# UUPS_367.0 register map
Vendor: Texas Instruments
Peripheral module from a debugger description file (folder msp430).
Registers are 16-bit, read-only, no defined reset value unless marked. A register's access mark holds for its fields unless they carry their own. Offsets are as the file gives them; lines under a group give offsets from that group; [hi:lo] are bit positions; {n}, {i} and the like mark numbered series; 'fields as' and 'values as' point back to an identical list; <NAME> marks a mode.

## UUPS
0x00 UUPSIIDX — Interrupt Index Register
  [15:1] IIDX — UUPS Interrupt Vector Value.
    0=No Interrupt pending; 1=Interrupt Source: PTMOUT; Interrupt Priority: Highest; 2=Interrupt Source: PREQIG; 3=Interrupt Source: STPBYDB; 4=Reserved; Interrupt Priority: Lowest
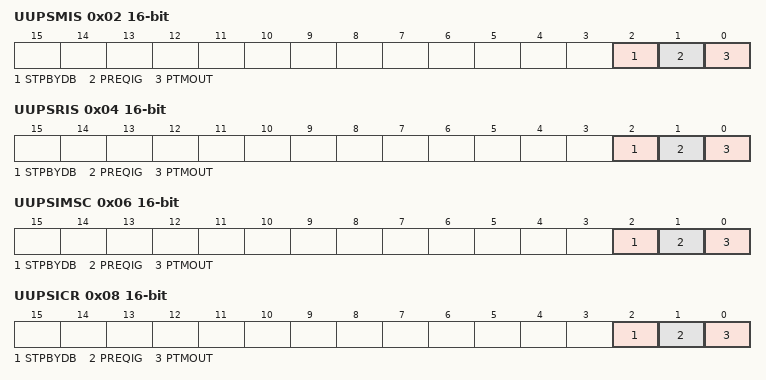
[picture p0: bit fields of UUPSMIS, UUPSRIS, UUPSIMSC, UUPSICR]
0x02 UUPSMIS — Masked Interrupt Status Register
  [all] fields
    0=No interrupt pending; 1=Interrupt pending
  [2] STPBYDB — USS has been interrupted by debug mode Masked Interrupt Status bit.
  [1] PREQIG — UUPS Power Request Ignore Masked Interrupt Status bit.
  [0] PTMOUT — UUPS Power Up Time Out Masked Interrupt Status bit.
0x04 UUPSRIS — Raw Interrupt Status Register
  [2] STPBYDB — USS has been interrupted by debug mode.
    0=USS has not been interrupted by debug halt mode; 1=USS has been interrupted by debug halt mode
  [1] PREQIG — UUPS Power Request Ignore Masked Interrupt Status and Clear bit.
    0=No USS_PWRREQ signal has been ignored; 1=USS_PWRREQ signal has been ignored
  [0] PTMOUT — UUPS Power Up Timer Out Raw Interrupt Status bit.
    0=Time out during power up has not occurred; 1=Time out during power up has occurred
0x06 UUPSIMSC rw — Interrupt Mask Register
  [2] STPBYDB — USS has been interrupted by debug mode Interrupt Mask bit.
    0=STPBYDB Interrupt is disabled; 1=STPBYDB Interrupt is enabled
  [1] PREQIG — Power Request Ignore Interrupt Mask bit.
    0=Power Request Ignore Interrupt is disabled; 1=Power Request Ignore Interrupt is enabled
  [0] PTMOUT — UUPS Power Up Time Out Interrupt Mask bit.
    0=UUPS Power Up Time Out Interrupt is disabled; 1=UUPS Power Up Time Out Interrupt is enabled
0x08 UUPSICR rw — Interrupt Clear Register.
  [2] STPBYDB — USS has been interrupted by debug mode Interrupt Clear bit.
  [1] PREQIG — Power Request Ignored Interrupt Clear bit.
  [0] PTMOUT — UUPS Power Up Time Out Interrupt Clear bit.
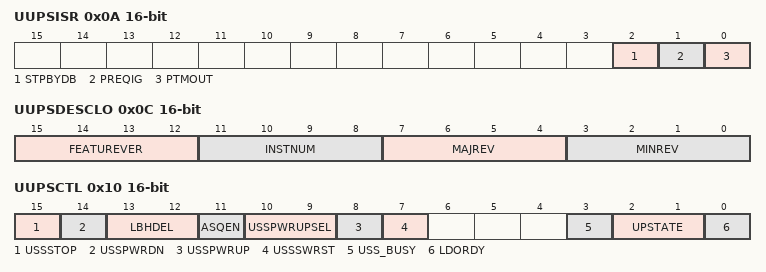
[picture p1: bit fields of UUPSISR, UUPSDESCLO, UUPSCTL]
0x0A UUPSISR rw — Interrupt Flag Set Register.
  [2] STPBYDB — USS has been interrupted by debug mode Interrupt Set bit.
  [1] PREQIG — Power Request Ignored Interrupt Set bit.
  [0] PTMOUT — UUPS Power Up Time Out Interrupt Set bit.
0x0C UUPSDESCLO — UUPS Descriptor Register L.
  [15:12] FEATUREVER — Feature Set for the module
  [11:8] INSTNUM — Instance Number within the device.
  [7:4] MAJREV — Major Revision
  [3:0] MINREV — Minor Revision
0x0E UUPSDESCHI access not given — UUPS Descriptor Register H.
0x10 UUPSCTL access per field — UUPS Control
  [15] USSSTOP rw — USS Measurement Stop
    0=No action; 1=Stop the current measurement
  [14] USSPWRDN rw — USS Power Down
    0=No action; 1=Stop the current measurement and power off the USS module
  [13:12] LBHDEL rw — Reserved_2
    0=no additional delay; 1=additional hold off delay of ~100us (512 REFCLKs); 2=additional hold off delay of ~200us (1024 REFCLKs); 3=additional hold off delay of ~300us (1536 REFCLKs)
  [11] ASQEN rw — Power Ready Output Event Select
    0=Do not generate the PSQ_START signal event to ASQ; 1=Generate the PSQ_START signal event to the ASQ
  [10:9] USSPWRUPSEL rw — USS Power Up trigger source select.
    0=CTL.USSPWRUP bit; 1=Ext. trigger (see the device specific datasheet); 2=Ext. trigger (see the device-specific data sheet); 3=Ext. trigger (see the device-specific data sheet)
  [8] USSPWRUP rw — Turn on USS Power and PLL
    0=No action; 1=Power up the USS module and generate the PSQ_START to the ASQ if CTL.ASQEN = 1. Note: This bit becomes invalid in debug mode.
  [7] USSSWRST rw — Software reset
    0=Disabled. USS (and sub modules) reset released for operation; 1=Enabled. USS (and sub modules) logic held in reset state
  [3] USS_BUSY ro — USS Busy bit.
    0=The USS module is not busy; 1=The USS module is busy
  [2:1] UPSTATE ro — USS Power Up trigger source select.
    0=USS is in OFF mode; 1=USS is in STANDBY mode; 2=USS power mode is in transition; 3=USS is in READY mode
  [0] LDORDY ro — USS LDO is ready
    0=USS LDO is powered down or in transition mode; 1=USS LDO is powered on
